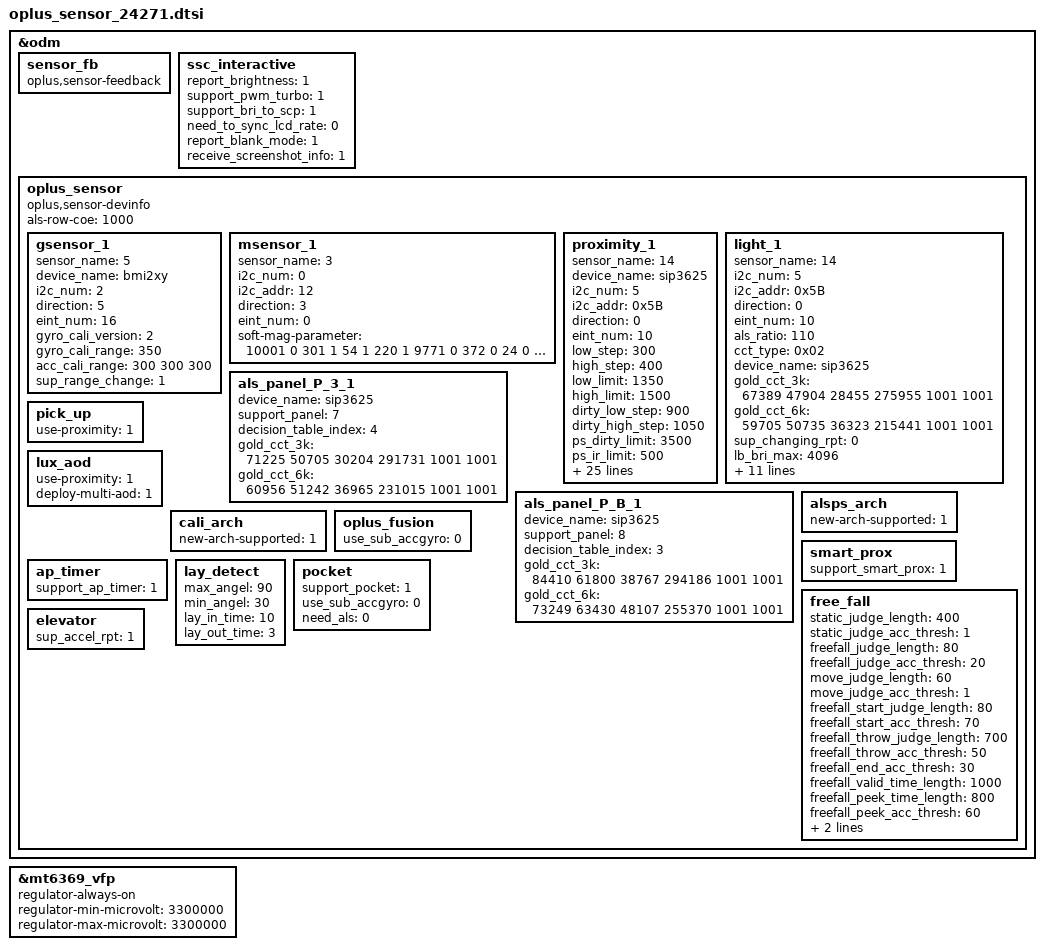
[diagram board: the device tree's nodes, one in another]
&odm {
	sensor_fb: sensor_fb {
		compatible = "oplus,sensor-feedback";
	};
	ssc_interactive: ssc_interactive {
		report_brightness = <1>;
		support_pwm_turbo = <1>;
		support_bri_to_scp = <1>;
		need_to_sync_lcd_rate = <0>;
		report_blank_mode = <1>;
                receive_screenshot_info = <1>;
	};
	oplus_sensor:oplus_sensor {
		compatible = "oplus,sensor-devinfo";
		als-row-coe = <1000>;
		/* sensor start */
		/*
		enum {
			LIS3DH,
			LSM6DS3,
			BMI160,
			LIS2HH12,
			LSM6DSM,
			BMI2XY,
			LSM6DSO,
			ICM4X6XX,
			ICM4263X,
			ICM4N607,
			BMI22X,
			SC7A20,
			MC34X9,
		};
		*/
		gsensor_1: gsensor_1 {
			status = "okay";
			sensor_name = <5>;//BMI2XY
			device_name = "bmi2xy";
			i2c_num = <2>;
			direction = <5>;
			eint_num = <16>;
			gyro_cali_version= <2>;
			gyro_cali_range =<350>;
			acc_cali_range= <300 300 300>;
			sup_range_change = <1>;
		};

		/*
		enum {
			AKM09911,
			MMC3530,
			MMC5603,
			MXG4300,
			AKM09918,
		};
		*/
		msensor_1: msensor_1 {
			status = "okay";
			sensor_name = <3>; // MXG4300
			i2c_num = <0>;
			i2c_addr = <12>;
			direction = <3>;
			eint_num = <0>;
			soft-mag-parameter = <10001 0 301 1 54 1 220 1 9771 0 372 0 24 0 153 1 10605 0>;
		};
		/*
		enum {
			TMD2725,
			APSD9922,
			STK3335,
			STK3331,
			STK2232,
			TCS3701,
			STK32600,
			STK33502,
			MN78911,
			TCS3720,
			SIP3515,
			STK3329,
			LTR569,
			SIP3510,
			SIP3625,
		};
		*/

		proximity_1: proximity_1 {
			status = "okay";
			sensor_name = <14>; // SIP3625
			device_name = "sip3625";
			i2c_num = <5>;
			i2c_addr = <0x5B>;
			direction = <0>;
			eint_num = <10>;
			low_step = <300>;
			high_step = <400>;
			low_limit = <1350>;
			high_limit = <1500>;
			dirty_low_step = <900>;
			dirty_high_step = <1050>;
			ps_dirty_limit = <3500>;
			ps_ir_limit = <500>;
			ps_adjust_min = <300>;
			ps_adjust_max = <1500>;
			sampling_count = <5>;
			step_max = <400>;
			step_min = <100>;
			step_div = <2000>;
			anti_shake_delta = <160>;
			dynamic_cali_max = <5114>;
			raw2offset_radio = <5000>;
			offset_max = <15000>;
			offset_range_min = <0>;
			offset_range_max = <65534>;
			force_cali_limit = <5116>;
			cali_jitter_limit = <70>;
			cal_offset_margin = <3000>;
			60hz_psd_us = <13800>;
			90hz_psd_us = <13800>;
			120hz_psd_us = <13800>;
			ps_check_num = <3>;
			ps_mid_filter = <0>;
			need_to_sync_lcd_rate = <0>;
			ps_power_config = <3>;
			dmc_flt_thr = <100>;
			multi_oft_level = <3>;
			multi_oft_coef = <130 26 1>;
		};
		light_1: light_1 {
			status = "okay";
			sensor_name = <14>;//SIP3625
			i2c_num = <5>;
			i2c_addr = <0x5B>;
			direction = <0>;
			eint_num = <10>;
			als_ratio = <110>;
			cct_type = <0x02>; //0x01 CCT_NORMAL 0x02 CCT_WISE
			device_name = "sip3625";
			gold_cct_3k = <67389 47904 28455 275955 1001 1001>;
			gold_cct_6k = <59705 50735 36323 215441 1001 1001>;
			sup_changing_rpt = <0>;
			lb_bri_max = <4096>;
			ir_ratio = <38>; // *1000
			lux_thod = <2000>;//add for high light mode
			idac_thod = <20>;//add for high light mode
			als_delay = <280>;
			available_sensor = <14>;
			gold_cct_factor = <941 946 924 966 1001 1001>;
			high_pwm_cct = <1>;
			als_timer_ms = <100>;
			als_buffer_length = <2>;
			atime = <8330>;
			need_gain_cali = <1>;
		};
		als_panel_P_3_1: als_panel_P_3_1 {
			status = "okay";
			device_name = "sip3625";
			support_panel = <7>;
                        decision_table_index = <4>;
			gold_cct_3k = <71225 50705 30204 291731 1001 1001>;
			gold_cct_6k = <60956 51242 36965 231015 1001 1001>;
		};
		als_panel_P_B_1: als_panel_P_B_1 {
			status = "okay";
			device_name = "sip3625";
			support_panel = <8>;
                        decision_table_index = <3>;
			gold_cct_3k = <84410 61800 38767 294186 1001 1001>;
			gold_cct_6k = <73249 63430 48107 255370 1001 1001>;
		};

		pick_up: pick_up {
			status = "okay";
			use-proximity = <1>;
		};
		lux_aod: lux_aod {
			status = "okay";
			use-proximity = <1>;
			deploy-multi-aod = <1>;
		};
		alsps_arch: alsps_arch {
			status = "okay";
			new-arch-supported = <1>;
		};
		cali_arch: cali_arch {
			status = "okay";
			new-arch-supported = <1>;
		};
		oplus_fusion: oplus_fusion {
			status = "okay";
			use_sub_accgyro = <0>;
		};
		smart_prox: smart_prox {
			status = "okay";
			support_smart_prox = <1>;
		};
		ap_timer: ap_timer {
			status = "okay";
			support_ap_timer = <1>;
		};
		lay_detect: lay_detect{
			status = "okay";
			max_angel = <90>;
			min_angel = <30>;
			lay_in_time = <10>;
			lay_out_time = <3>;
		};
                pocket: pocket {
			status = "okay";
			support_pocket = <1>;
			use_sub_accgyro = <0>;
			need_als = <0>;
		};
		free_fall: free_fall{
			status = "okay";
			static_judge_length = <400>;
			static_judge_acc_thresh = <1>;
			freefall_judge_length = <80>;
			freefall_judge_acc_thresh = <20>;
			move_judge_length = <60>;
			move_judge_acc_thresh = <1>;
			freefall_start_judge_length  = <80>;
			freefall_start_acc_thresh = <70>;
			freefall_throw_judge_length = <700>;
			freefall_throw_acc_thresh = <50>;
			freefall_end_acc_thresh = <30>;
			freefall_valid_time_length = <1000>;
			freefall_peek_time_length = <800>;
			freefall_peek_acc_thresh = <60>;
			freefall_material_thresh = <900>;
			valid_peek_interval_thresh = <10000>;
		};
		elevator: elevator{
			status = "okay";
			sup_accel_rpt = <1>;
		};
	};
/* sensor end */
};

&mt6369_vfp {
	regulator-always-on;
        regulator-min-microvolt = <3300000>;
        regulator-max-microvolt = <3300000>;
};
